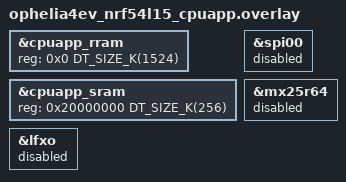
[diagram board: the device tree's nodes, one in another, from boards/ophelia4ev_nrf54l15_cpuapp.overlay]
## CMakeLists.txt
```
#
# Copyright (c) 2021 Nordic Semiconductor ASA
#
# SPDX-License-Identifier: LicenseRef-Nordic-5-Clause
#

cmake_minimum_required(VERSION 3.20.0)

find_package(Zephyr HINTS $ENV{ZEPHYR_BASE})

project(matter_ophelia4)

# Enable GNU STD support.
include(${ZEPHYR_CONNECTEDHOMEIP_MODULE_DIR}/config/nrfconnect/app/enable-gnu-std.cmake)

# NORDIC SDK APP START

# Include all source files that are located in the Matter common directory.
include(${ZEPHYR_NRF_MODULE_DIR}/samples/matter/common/cmake/source_common.cmake)

# Include Data Model utils
include(${ZEPHYR_NRF_MODULE_DIR}/samples/matter/common/cmake/data_model.cmake)

include(${ZEPHYR_NRF_MODULE_DIR}/samples/matter/common/cmake/zap_helpers.cmake)
ncs_get_zap_parent_dir(ZAP_PARENT_DIR)

target_include_directories(app PRIVATE
  src
  ${ZAP_PARENT_DIR}
)

target_sources(app PRIVATE
  src/app_task.cpp
  src/main.cpp
  src/dfu_stub.c
  src/humidity_sensor.cpp
)

ncs_configure_data_model()
# NORDIC SDK APP END
```

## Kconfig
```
#
# Copyright (c) 2022 Nordic Semiconductor
#
# SPDX-License-Identifier: LicenseRef-Nordic-5-Clause
#
mainmenu "Matter nRF Connect Template Example Application"

# Sample configuration used for Thread networking
if OPENTHREAD

choice OPENTHREAD_NORDIC_LIBRARY_CONFIGURATION
	default OPENTHREAD_NORDIC_LIBRARY_FTD
endchoice

choice OPENTHREAD_DEVICE_TYPE
	default OPENTHREAD_FTD
endchoice

endif # OPENTHREAD

config CHIP_WIFI
	default y if BOARD_NRF7002DK_NRF5340_CPUAPP || SHIELD_NRF7002EB2
	select DEPRECATED if SOC_SERIES_NRF53X

source "$(ZEPHYR_CONNECTEDHOMEIP_MODULE_DIR)/config/nrfconnect/chip-module/Kconfig.features"
source "$(ZEPHYR_CONNECTEDHOMEIP_MODULE_DIR)/config/nrfconnect/chip-module/Kconfig.defaults"
source "$(ZEPHYR_NRF_MODULE_DIR)/samples/matter/common/src/Kconfig"
source "Kconfig.zephyr"
```

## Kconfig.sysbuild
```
#
# Copyright (c) 2023 Nordic Semiconductor ASA
#
# SPDX-License-Identifier: LicenseRef-Nordic-5-Clause
#

# This config has to be enabled manually for variants with shields, because sysbuild does not support it.
config WIFI_NRF70
	default y if BOARD_NRF7002DK

#### Radio core selection
config NRF_DEFAULT_IPC_RADIO
	default y

# Enable IEEE802.15.4 serialization to network core
# This config automatically pulls in the `overlay-802154.conf` in the ipc_radio image
config NETCORE_IPC_RADIO_IEEE802154
	default y if SOC_SERIES_NRF53X && !WIFI_NRF70

# Enable Bluetooth serialization to network core
# This config automatically pulls in the `overlay-bt_hci_ipc.conf` in the ipc_radio image
config NETCORE_IPC_RADIO_BT_HCI_IPC
	default y if SOC_SERIES_NRF53X

#### Bootloader
choice BOOTLOADER
	default BOOTLOADER_MCUBOOT if !BOARD_NRF21540DK
endchoice

if BOOTLOADER_MCUBOOT

#### DFU multi-image support
config DFU_MULTI_IMAGE_PACKAGE_BUILD
	default y

config DFU_MULTI_IMAGE_PACKAGE_APP
	default y

config PM_EXTERNAL_FLASH_MCUBOOT_SECONDARY
	default n if BOARD_OPHELIA4EV
	default y

#### DFU network core configuration
if SOC_SERIES_NRF53X

choice MCUBOOT_MODE
	default MCUBOOT_MODE_OVERWRITE_ONLY
endchoice

choice BOOT_SIGNATURE_TYPE
	default BOOT_SIGNATURE_TYPE_RSA
endchoice

config SECURE_BOOT_NETCORE
	default y

config NETCORE_APP_UPDATE
	default y

config DFU_MULTI_IMAGE_PACKAGE_NET
	default y

endif # SOC_SERIES_NRF53X

if BOARD_NRF54L15DK || BOARD_NRF54LM20DK || BOARD_OPHELIA4EV

# Disable checking the external drivers for nRF54L15 and nRF54LM20 DKs.
config PM_OVERRIDE_EXTERNAL_DRIVER_CHECK
	default y

endif # BOARD_NRF54L15DK || BOARD_NRF54LM20DK || BOARD_OPHELIA4EV

# Mcuboot padding size is modified to 0x1000 in pm_static file.
if SOC_NRF54L10

config PM_MCUBOOT_PAD
	default 0x1000

endif # SOC_NRF54L10

endif # BOOTLOADER_MCUBOOT

# Store the Wi-Fi firmware patch on external flash by default for nRF5340 with nRF7002
if WIFI_NRF70 && SOC_NRF5340_CPUAPP

choice WIFI_PATCHES_EXT_FLASH_SUPPORT
	default WIFI_PATCHES_EXT_FLASH_STORE

endchoice

config DFU_MULTI_IMAGE_PACKAGE_WIFI_FW_PATCH
	default y

endif # WIFI_NRF70

#### Enable generating factory data
config MATTER_FACTORY_DATA_GENERATE
	default y if !BOARD_NRF21540DK

source "share/sysbuild/Kconfig"
```

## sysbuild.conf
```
#
# Copyright (c) 2024 Nordic Semiconductor
#
# SPDX-License-Identifier: LicenseRef-Nordic-5-Clause
#

SB_CONFIG_MATTER=y
SB_CONFIG_BOOTLOADER_NONE=y
SB_CONFIG_MATTER_FACTORY_DATA_GENERATE=n
SB_CONFIG_PM_EXTERNAL_FLASH_MCUBOOT_SECONDARY=n
```

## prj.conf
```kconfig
#
# Copyright (c) 2021 Nordic Semiconductor ASA
#
# SPDX-License-Identifier: LicenseRef-Nordic-5-Clause
#

# This sample uses Kconfig.defaults to set options common for all
# samples. This file should contain only options specific for this sample
# or overrides of default values.

# Enable CHIP
CONFIG_CHIP=y
CONFIG_CHIP_PROJECT_CONFIG="src/chip_project_config.h"
CONFIG_CHIP_DEVICE_PRODUCT_NAME="Matter Template"

# Configure ZAP file name
CONFIG_NCS_SAMPLE_MATTER_ZAP_FILE_PATH="${APPLICATION_CONFIG_DIR}/src/default_zap/template.zap"

# 32768 == 0x8000 (example Product ID added temporaly,
# but it must be changed with proper PID from the list:
# https://github.com/project-chip/connectedhomeip/blob/482e6fd03196a6de45465a90003947ef4b86e0b1/docs/examples/discussion/PID_allocation_for_example_apps.md)
CONFIG_CHIP_DEVICE_PRODUCT_ID=32768
CONFIG_STD_CPP17=y

# Enable Matter pairing automatically on application start.
CONFIG_CHIP_ENABLE_PAIRING_AUTOSTART=y

# Enable Matter extended announcement and increase duration to 1 hour.
CONFIG_CHIP_BLE_EXT_ADVERTISING=y
CONFIG_CHIP_BLE_ADVERTISING_DURATION=60

# Add support for LEDs and buttons on Nordic development kits
CONFIG_DK_LIBRARY=n

# Bluetooth Low Energy configuration
CONFIG_BT_DEVICE_NAME="MatterOphelia4"

# Other settings
CONFIG_THREAD_NAME=y
CONFIG_MPU_STACK_GUARD=y
CONFIG_RESET_ON_FATAL_ERROR=n
CONFIG_CHIP_LIB_SHELL=y
CONFIG_NCS_SAMPLE_MATTER_TEST_SHELL=y

# Disable NFC onboarding
CONFIG_CHIP_NFC_ONBOARDING_PAYLOAD=n

# Disable DFU/MCUboot support (no bootloader for now)
CONFIG_CHIP_BOOTLOADER_NONE=y

# No bootloader, no OTA, no DFU image manager
CONFIG_CHIP_OTA_REQUESTOR=n
CONFIG_IMG_MANAGER=n

# Reduce application size
# Segger RTT console (via Segger EDU Mini on CON2)
CONFIG_USE_SEGGER_RTT=y
CONFIG_RTT_CONSOLE=y
CONFIG_UART_CONSOLE=n

# Enable Factory Data feature
CONFIG_CHIP_FACTORY_DATA=n
CONFIG_CHIP_FACTORY_DATA_BUILD=n

# Reduce Thread polling interval for Google Home compatibility
CONFIG_OPENTHREAD_POLL_PERIOD=500
```

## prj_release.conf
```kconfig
#
# Copyright (c) 2021 Nordic Semiconductor ASA
#
# SPDX-License-Identifier: LicenseRef-Nordic-5-Clause
#

# This sample uses Kconfig.defaults to set options common for all
# samples. This file should contain only options specific for this sample
# or overrides of default values.

# Enable CHIP
CONFIG_CHIP=y
CONFIG_CHIP_PROJECT_CONFIG="src/chip_project_config.h"
CONFIG_CHIP_DEVICE_PRODUCT_NAME="Matter Template"

# Configure ZAP file name
CONFIG_NCS_SAMPLE_MATTER_ZAP_FILE_PATH="${APPLICATION_CONFIG_DIR}/src/default_zap/template.zap"

# 32768 == 0x8000 (example Product ID added temporaly,
# but it must be changed with proper PID from the list:
# https://github.com/project-chip/connectedhomeip/blob/482e6fd03196a6de45465a90003947ef4b86e0b1/docs/examples/discussion/PID_allocation_for_example_apps.md)
CONFIG_CHIP_DEVICE_PRODUCT_ID=32768
CONFIG_STD_CPP17=y

# Enable Matter pairing automatically on application start.
CONFIG_CHIP_ENABLE_PAIRING_AUTOSTART=y

# Enable Matter extended announcement and increase duration to 1 hour.
CONFIG_CHIP_BLE_EXT_ADVERTISING=y
CONFIG_CHIP_BLE_ADVERTISING_DURATION=60

# Add support for LEDs and buttons on Nordic development kits
CONFIG_DK_LIBRARY=y

# Bluetooth Low Energy configuration
CONFIG_BT_DEVICE_NAME="MatterTemplate"

# Enable system reset on fatal error
CONFIG_RESET_ON_FATAL_ERROR=y

# Disable all debug features
CONFIG_USE_SEGGER_RTT=n
CONFIG_SHELL=n
CONFIG_OPENTHREAD_SHELL=n
CONFIG_CHIP_LIB_SHELL=n
CONFIG_CONSOLE=n
CONFIG_UART_CONSOLE=n
CONFIG_SERIAL=n
CONFIG_LOG=n
CONFIG_LOG_MODE_MINIMAL=n
CONFIG_ASSERT_VERBOSE=n
CONFIG_ASSERT_NO_FILE_INFO=y
CONFIG_PRINTK=n
CONFIG_PRINTK_SYNC=n
CONFIG_THREAD_NAME=n
CONFIG_BOOT_BANNER=n

# Disable NFC onboarding
CONFIG_CHIP_NFC_ONBOARDING_PAYLOAD=n

# Enable Factory Data feature
CONFIG_CHIP_FACTORY_DATA=n
CONFIG_CHIP_FACTORY_DATA_BUILD=n

# Enable Watchdog
CONFIG_NCS_SAMPLE_MATTER_WATCHDOG=y

# Enable LTO to decrease the flash usage.
CONFIG_LTO=y
CONFIG_ISR_TABLES_LOCAL_DECLARATION=y
```

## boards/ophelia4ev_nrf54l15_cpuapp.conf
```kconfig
# Ophelia-IV MiniEV specific configuration

# Disable UART hw-flow-control (MiniEV CON4 has no CTS/RTS wired by default)
CONFIG_UART_USE_RUNTIME_CONFIGURE=y

# Use internal LFRC oscillator (MiniEV has no LFXO crystal by default)
CONFIG_CLOCK_CONTROL_NRF_K32SRC_RC=y
```

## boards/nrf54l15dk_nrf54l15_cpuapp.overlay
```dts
/* Ophelia-IV MiniEV - override nRF54L15 DK defaults */

/* Restore full RRAM and SRAM */
&cpuapp_rram {
    reg = <0x0 DT_SIZE_K(1524)>;
};

&cpuapp_sram {
    reg = <0x20000000 DT_SIZE_K(256)>;
    ranges = <0x0 0x20000000 0x40000>;
};

/* No external flash on Ophelia-IV MiniEV */
&mx25r64 {
    status = "disabled";
};

/* Disable UART hw-flow-control */
&uart20 {
    /delete-property/ hw-flow-control;
};
```

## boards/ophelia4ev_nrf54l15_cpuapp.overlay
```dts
/* Ophelia-IV MiniEV - no external SPI flash, no user LEDs/buttons */

/* Restore full RRAM and SRAM (no FLPR reservation) */
&cpuapp_rram {
    reg = <0x0 DT_SIZE_K(1524)>;
};

&cpuapp_sram {
    reg = <0x20000000 DT_SIZE_K(256)>;
    ranges = <0x0 0x20000000 0x40000>;
};

/* MiniEV has no external SPI flash */
&spi00 {
    status = "disabled";
};

&mx25r64 {
    status = "disabled";
};

/* MiniEV has no LFXO crystal (Q1, C9, C10 not assembled) - use LFRC */
&lfxo {
    status = "disabled";
};
```

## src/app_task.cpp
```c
/*
 * Copyright (c) 2021 Nordic Semiconductor ASA
 *
 * SPDX-License-Identifier: LicenseRef-Nordic-5-Clause
 */

#include "app_task.h"

#include "app/matter_init.h"
#include "app/task_executor.h"
#include "board/board.h"
#include "lib/core/CHIPError.h"
#include "lib/support/CodeUtils.h"

#include <setup_payload/OnboardingCodesUtil.h>

#include <zephyr/logging/log.h>

#include "humidity_sensor.h"

LOG_MODULE_DECLARE(app, CONFIG_CHIP_APP_LOG_LEVEL);

using namespace ::chip;
using namespace ::chip::app;
using namespace ::chip::DeviceLayer;

CHIP_ERROR AppTask::Init()
{
	/* Initialize Matter stack */
	ReturnErrorOnFailure(Nrf::Matter::PrepareServer());

	/* Add Humidity Sensor endpoint */
	ReturnErrorOnFailure(InitHumiditySensorEndpoint());

	/* Set initial humidity value (50.00% RH for testing) */
	SetMeasuredHumidity(5000);

	if (!Nrf::GetBoard().Init()) {
		LOG_ERR("User interface initialization failed.");
		return CHIP_ERROR_INCORRECT_STATE;
	}

	/* Register Matter event handler that controls the connectivity status LED based on the captured Matter network
	 * state. */
	ReturnErrorOnFailure(Nrf::Matter::RegisterEventHandler(Nrf::Board::DefaultMatterEventHandler, 0));

	return Nrf::Matter::StartServer();
}

CHIP_ERROR AppTask::StartApp()
{
	ReturnErrorOnFailure(Init());

	while (true) {
		Nrf::DispatchNextTask();
	}

	return CHIP_NO_ERROR;
}
```

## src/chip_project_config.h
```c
/*
 * Copyright (c) 2021 Nordic Semiconductor ASA
 *
 * SPDX-License-Identifier: LicenseRef-Nordic-5-Clause
 */

/**
 *    @file
 *          Example project configuration file for CHIP.
 *
 *          This is a place to put application or project-specific overrides
 *          to the default configuration values for general CHIP features.
 *
 */

#pragma once

/* No MCUboot bootloader - provide fallback for OTA code that references MCUboot config */
#ifndef CONFIG_UPDATEABLE_IMAGE_NUMBER
#define CONFIG_UPDATEABLE_IMAGE_NUMBER 1
#endif
```

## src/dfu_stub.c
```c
/*
 * Stub for DFU target MCUboot functions.
 * Required because the Matter GN build compiles OTAImageProcessorImpl.cpp
 * even when OTA/MCUboot is disabled.
 */
#include <errno.h>
#include <stddef.h>
#include <stdint.h>

int dfu_target_mcuboot_set_buf(uint8_t *buf, size_t len)
{
    (void)buf;
    (void)len;
    return -ENOTSUP;
}
```

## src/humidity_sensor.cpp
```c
#include "humidity_sensor.h"

#include <app-common/zap-generated/ids/Attributes.h>
#include <app-common/zap-generated/ids/Clusters.h>
#include <app/reporting/reporting.h>
#include <app/util/attribute-storage.h>
#include <app/util/endpoint-config-api.h>
#include <lib/core/DataModelTypes.h>
#include <protocols/interaction_model/StatusCode.h>

#include <zephyr/logging/log.h>

LOG_MODULE_REGISTER(humidity_sensor, CONFIG_CHIP_APP_LOG_LEVEL);

using namespace chip;
using namespace chip::app;
using namespace chip::app::Clusters;
using chip::Protocols::InteractionModel::Status;

/* Endpoint 1 configuration */
static constexpr EndpointId kHumidityEndpointId = 1;
static constexpr uint16_t kHumidityDeviceType = 0x0100; /* On/Off Light */

/* Attribute storage for Relative Humidity Measurement cluster (0x0405) */
static uint16_t sMeasuredValue = 0;
static uint16_t sMinMeasuredValue = 0;
static uint16_t sMaxMeasuredValue = 10000;

/* Attribute storage for Identify cluster (0x0003) */
static uint16_t sIdentifyTime = 0;
static uint8_t sIdentifyType = 0; /* None */

/* Attribute storage for OnOff cluster (0x0006) */
static bool sOnOffValue = false;

static constexpr EmberAfAttributeMetadata sOnOffAttrs[] = {
    /* OnOff */
    { ZAP_SIMPLE_DEFAULT(0), 0x0000, 1, ZAP_TYPE(BOOLEAN),
      ZAP_ATTRIBUTE_MASK(EXTERNAL_STORAGE) | ZAP_ATTRIBUTE_MASK(READABLE) },
    /* FeatureMap */
    { ZAP_EMPTY_DEFAULT(), 0xFFFC, 4, ZAP_TYPE(BITMAP32),
      ZAP_ATTRIBUTE_MASK(EXTERNAL_STORAGE) | ZAP_ATTRIBUTE_MASK(READABLE) },
    /* ClusterRevision */
    { ZAP_SIMPLE_DEFAULT(6), 0xFFFD, 2, ZAP_TYPE(INT16U),
      ZAP_ATTRIBUTE_MASK(READABLE) },
};

// clang-format off

/* Identify cluster attributes (0x0003) - MANDATORY for Humidity Sensor */
static constexpr EmberAfAttributeMetadata sIdentifyAttrs[] = {
    /* IdentifyTime */
    { ZAP_SIMPLE_DEFAULT(0), 0x0000, 2, ZAP_TYPE(INT16U),
      ZAP_ATTRIBUTE_MASK(EXTERNAL_STORAGE) | ZAP_ATTRIBUTE_MASK(READABLE) | ZAP_ATTRIBUTE_MASK(WRITABLE) },
    /* IdentifyType */
    { ZAP_SIMPLE_DEFAULT(0), 0x0001, 1, ZAP_TYPE(ENUM8),
      ZAP_ATTRIBUTE_MASK(EXTERNAL_STORAGE) | ZAP_ATTRIBUTE_MASK(READABLE) },
    /* FeatureMap */
    { ZAP_EMPTY_DEFAULT(), 0xFFFC, 4, ZAP_TYPE(BITMAP32),
      ZAP_ATTRIBUTE_MASK(EXTERNAL_STORAGE) | ZAP_ATTRIBUTE_MASK(READABLE) },
    /* ClusterRevision */
    { ZAP_SIMPLE_DEFAULT(4), 0xFFFD, 2, ZAP_TYPE(INT16U),
      ZAP_ATTRIBUTE_MASK(READABLE) },
};

/* RelativeHumidityMeasurement cluster attributes (0x0405) */
static constexpr EmberAfAttributeMetadata sHumidityAttrs[] = {
    /* MeasuredValue */
    { ZAP_EMPTY_DEFAULT(), 0x0000, 2, ZAP_TYPE(INT16U),
      ZAP_ATTRIBUTE_MASK(EXTERNAL_STORAGE) | ZAP_ATTRIBUTE_MASK(READABLE) | ZAP_ATTRIBUTE_MASK(NULLABLE) },
    /* MinMeasuredValue */
    { ZAP_EMPTY_DEFAULT(), 0x0001, 2, ZAP_TYPE(INT16U),
      ZAP_ATTRIBUTE_MASK(EXTERNAL_STORAGE) | ZAP_ATTRIBUTE_MASK(READABLE) | ZAP_ATTRIBUTE_MASK(NULLABLE) },
    /* MaxMeasuredValue */
    { ZAP_EMPTY_DEFAULT(), 0x0002, 2, ZAP_TYPE(INT16U),
      ZAP_ATTRIBUTE_MASK(EXTERNAL_STORAGE) | ZAP_ATTRIBUTE_MASK(READABLE) | ZAP_ATTRIBUTE_MASK(NULLABLE) },
    /* FeatureMap */
    { ZAP_EMPTY_DEFAULT(), 0xFFFC, 4, ZAP_TYPE(BITMAP32),
      ZAP_ATTRIBUTE_MASK(EXTERNAL_STORAGE) | ZAP_ATTRIBUTE_MASK(READABLE) },
    /* ClusterRevision */
    { ZAP_SIMPLE_DEFAULT(3), 0xFFFD, 2, ZAP_TYPE(INT16U),
      ZAP_ATTRIBUTE_MASK(READABLE) },
};

/* Descriptor cluster attributes (0x001D) */
static constexpr EmberAfAttributeMetadata sDescriptorAttrs[] = {
    /* DeviceTypeList */
    { ZAP_EMPTY_DEFAULT(), 0x0000, 0, ZAP_TYPE(ARRAY),
      ZAP_ATTRIBUTE_MASK(EXTERNAL_STORAGE) | ZAP_ATTRIBUTE_MASK(READABLE) },
    /* ServerList */
    { ZAP_EMPTY_DEFAULT(), 0x0001, 0, ZAP_TYPE(ARRAY),
      ZAP_ATTRIBUTE_MASK(EXTERNAL_STORAGE) | ZAP_ATTRIBUTE_MASK(READABLE) },
    /* ClientList */
    { ZAP_EMPTY_DEFAULT(), 0x0002, 0, ZAP_TYPE(ARRAY),
      ZAP_ATTRIBUTE_MASK(EXTERNAL_STORAGE) | ZAP_ATTRIBUTE_MASK(READABLE) },
    /* PartsList */
    { ZAP_EMPTY_DEFAULT(), 0x0003, 0, ZAP_TYPE(ARRAY),
      ZAP_ATTRIBUTE_MASK(EXTERNAL_STORAGE) | ZAP_ATTRIBUTE_MASK(READABLE) },
    /* FeatureMap */
    { ZAP_EMPTY_DEFAULT(), 0xFFFC, 4, ZAP_TYPE(BITMAP32),
      ZAP_ATTRIBUTE_MASK(EXTERNAL_STORAGE) | ZAP_ATTRIBUTE_MASK(READABLE) },
    /* ClusterRevision */
    { ZAP_SIMPLE_DEFAULT(2), 0xFFFD, 2, ZAP_TYPE(INT16U),
      ZAP_ATTRIBUTE_MASK(READABLE) },
};
// clang-format on

/* Identify command lists */
static constexpr CommandId sIdentifyAcceptedCommands[] = {
    0x0000, /* Identify */
    0x0040, /* TriggerEffect */
    kInvalidCommandId,
};

static constexpr EmberAfCluster sHumidityClusters[] = {
    {
        .clusterId = Descriptor::Id,
        .attributes = sDescriptorAttrs,
        .attributeCount = ARRAY_SIZE(sDescriptorAttrs),
        .clusterSize = 0,
        .mask = ZAP_CLUSTER_MASK(SERVER),
        .functions = nullptr,
        .acceptedCommandList = nullptr,
        .generatedCommandList = nullptr,
        .eventList = nullptr,
        .eventCount = 0,
    },
    {
        .clusterId = Identify::Id,
        .attributes = sIdentifyAttrs,
        .attributeCount = ARRAY_SIZE(sIdentifyAttrs),
        .clusterSize = 0,
        .mask = ZAP_CLUSTER_MASK(SERVER),
        .functions = nullptr,
        .acceptedCommandList = sIdentifyAcceptedCommands,
        .generatedCommandList = nullptr,
        .eventList = nullptr,
        .eventCount = 0,
    },
    {
        .clusterId = RelativeHumidityMeasurement::Id,
        .attributes = sHumidityAttrs,
        .attributeCount = ARRAY_SIZE(sHumidityAttrs),
        .clusterSize = 0,
        .mask = ZAP_CLUSTER_MASK(SERVER),
        .functions = nullptr,
        .acceptedCommandList = nullptr,
        .generatedCommandList = nullptr,
        .eventList = nullptr,
        .eventCount = 0,
    },
    {
        .clusterId = OnOff::Id,
        .attributes = sOnOffAttrs,
        .attributeCount = ARRAY_SIZE(sOnOffAttrs),
        .clusterSize = 0,
        .mask = ZAP_CLUSTER_MASK(SERVER),
        .functions = nullptr,
        .acceptedCommandList = nullptr,
        .generatedCommandList = nullptr,
        .eventList = nullptr,
        .eventCount = 0,
    },
};

static constexpr EmberAfEndpointType sHumidityEndpoint = {
    .cluster = sHumidityClusters,
    .clusterCount = ARRAY_SIZE(sHumidityClusters),
    .endpointSize = 0,
};

static constexpr EmberAfDeviceType sDeviceTypeArray[] = {
    { kHumidityDeviceType, 2 },
};

static const Span<const EmberAfDeviceType> sDeviceTypes(sDeviceTypeArray);

static DataVersion sDataVersions[ARRAY_SIZE(sHumidityClusters)];

/* External attribute read callback */
Status emberAfExternalAttributeReadCallback(
    EndpointId endpoint, ClusterId clusterId,
    const EmberAfAttributeMetadata *attributeMetadata,
    uint8_t *buffer, uint16_t maxReadLength)
{
    if (endpoint != kHumidityEndpointId) {
        return Status::Failure;
    }

    uint16_t attrId = attributeMetadata->attributeId;

    if (clusterId == Identify::Id) {
        if (attrId == 0x0000) { /* IdentifyTime */
            memcpy(buffer, &sIdentifyTime, sizeof(sIdentifyTime));
            return Status::Success;
        }
        if (attrId == 0x0001) { /* IdentifyType */
            memcpy(buffer, &sIdentifyType, sizeof(sIdentifyType));
            return Status::Success;
        }
        if (attrId == 0xFFFC) { /* FeatureMap */
            uint32_t featureMap = 0;
            memcpy(buffer, &featureMap, sizeof(featureMap));
            return Status::Success;
        }
    }

    if (clusterId == RelativeHumidityMeasurement::Id) {
        if (attrId == 0x0000) {
            memcpy(buffer, &sMeasuredValue, sizeof(sMeasuredValue));
            return Status::Success;
        }
        if (attrId == 0x0001) {
            memcpy(buffer, &sMinMeasuredValue, sizeof(sMinMeasuredValue));
            return Status::Success;
        }
        if (attrId == 0x0002) {
            memcpy(buffer, &sMaxMeasuredValue, sizeof(sMaxMeasuredValue));
            return Status::Success;
        }
        if (attrId == 0xFFFC) {
            uint32_t featureMap = 0;
            memcpy(buffer, &featureMap, sizeof(featureMap));
            return Status::Success;
        }
    }

    if (clusterId == OnOff::Id) {
        if (attrId == 0x0000) { /* OnOff */
            memcpy(buffer, &sOnOffValue, sizeof(sOnOffValue));
            return Status::Success;
        }
        if (attrId == 0xFFFC) { /* FeatureMap */
            uint32_t featureMap = 0;
            memcpy(buffer, &featureMap, sizeof(featureMap));
            return Status::Success;
        }
    }

    return Status::Failure;
}

/* External attribute write callback (needed for Identify IdentifyTime) */
Status emberAfExternalAttributeWriteCallback(
    EndpointId endpoint, ClusterId clusterId,
    const EmberAfAttributeMetadata *attributeMetadata,
    uint8_t *buffer)
{
    if (endpoint != kHumidityEndpointId) {
        return Status::Failure;
    }

    if (clusterId == Identify::Id && attributeMetadata->attributeId == 0x0000) {
        memcpy(&sIdentifyTime, buffer, sizeof(sIdentifyTime));
        return Status::Success;
    }

    return Status::Failure;
}

CHIP_ERROR InitHumiditySensorEndpoint()
{
    CHIP_ERROR err = emberAfSetDynamicEndpoint(
        0,
        kHumidityEndpointId,
        &sHumidityEndpoint,
        Span<DataVersion>(sDataVersions),
        sDeviceTypes);

    if (err != CHIP_NO_ERROR) {
        LOG_ERR("Failed to add humidity endpoint: %" CHIP_ERROR_FORMAT, err.Format());
    } else {
        LOG_INF("Humidity Sensor endpoint %d added successfully", kHumidityEndpointId);
    }

    return err;
}

void SetMeasuredHumidity(uint16_t value)
{
    sMeasuredValue = value;
    MatterReportingAttributeChangeCallback(
        kHumidityEndpointId,
        RelativeHumidityMeasurement::Id,
        RelativeHumidityMeasurement::Attributes::MeasuredValue::Id);
}
```

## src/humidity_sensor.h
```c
/*
 * Humidity Sensor - Dynamic Endpoint for Matter
 * Device Type: Humidity Sensor (0x0015)
 * Cluster: Relative Humidity Measurement (0x0405)
 */

#pragma once

#include <lib/core/CHIPError.h>

CHIP_ERROR InitHumiditySensorEndpoint();
void SetMeasuredHumidity(uint16_t value);
```
